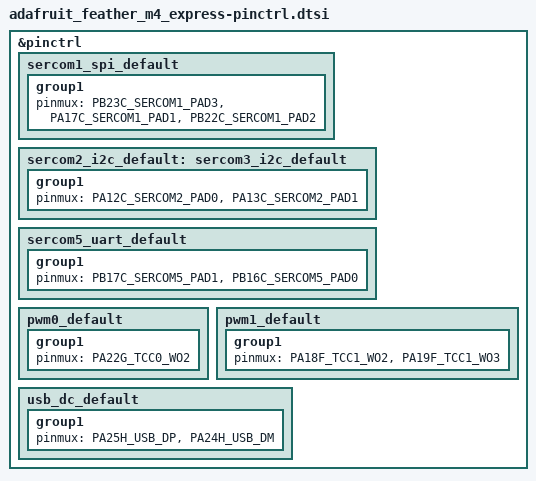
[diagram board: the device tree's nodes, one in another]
/*
 * Copyright (c) 2022, Gerson Fernando Budke <nandojve@gmail.com>
 * Copyright (c) 2024 Daikin Comfort Technologies North America, Inc.
 *
 * SPDX-License-Identifier: Apache-2.0
 */

#include <dt-bindings/pinctrl/samd51j-pinctrl.h>

&pinctrl {
	sercom1_spi_default: sercom1_spi_default {
		group1 {
			pinmux = <PB23C_SERCOM1_PAD3>,
				 <PA17C_SERCOM1_PAD1>,
				 <PB22C_SERCOM1_PAD2>;
		};
	};

	sercom2_i2c_default: sercom3_i2c_default {
		group1 {
			pinmux = <PA12C_SERCOM2_PAD0>,
				 <PA13C_SERCOM2_PAD1>;
		};
	};

	sercom5_uart_default: sercom5_uart_default {
		group1 {
			pinmux = <PB17C_SERCOM5_PAD1>,
				 <PB16C_SERCOM5_PAD0>;
		};
	};

	pwm0_default: pwm0_default {
		group1 {
			pinmux = <PA22G_TCC0_WO2>;
		};
	};
	pwm1_default: pwm1_default {
		group1 {
			pinmux = <PA18F_TCC1_WO2>,
				 <PA19F_TCC1_WO3>;
		};
	};

	usb_dc_default: usb_dc_default {
		group1 {
			pinmux = <PA25H_USB_DP>,
				 <PA24H_USB_DM>;
		};
	};
};
